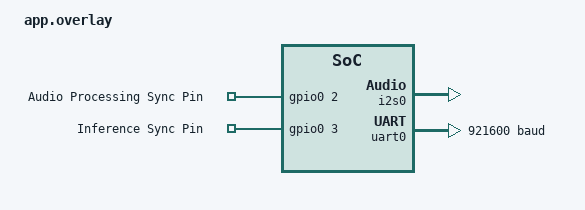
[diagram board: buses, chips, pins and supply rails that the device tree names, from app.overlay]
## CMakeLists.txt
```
# Copyright (c) 2026 Seeed Studio / Senior ML Engineer
# SPDX-License-Identifier: Apache-2.0

cmake_minimum_required(VERSION 3.20.0)

# Find Zephyr package
find_package(Zephyr REQUIRED HINTS $ENV{ZEPHYR_BASE})
project(streamable_kws_zephyr)

# Include esp-dl path (located in parent directory)
set(ESPDL_PATH ${CMAKE_CURRENT_SOURCE_DIR}/../esp-dl/esp-dl)
set(DL_FFT_PATH ${CMAKE_CURRENT_SOURCE_DIR}/../esp-dl/tools/dl_fft)

# ============================================================
# ESP-IDF HAL Paths (for PDM support)
# ============================================================
set(ESP_HAL_PATH ${CMAKE_CURRENT_SOURCE_DIR}/../zephyrproject/modules/hal/espressif)

target_include_directories(app PRIVATE
    src/compat
    ${ESPDL_PATH}/dl
    ${ESPDL_PATH}/dl/tool/include
    ${ESPDL_PATH}/dl/tensor/include
    ${ESPDL_PATH}/dl/base
    ${ESPDL_PATH}/dl/base/isa
    ${ESPDL_PATH}/dl/base/isa/tie728
    ${ESPDL_PATH}/dl/base/isa/xtensa
    ${ESPDL_PATH}/dl/math/include
    ${ESPDL_PATH}/dl/model/include
    ${ESPDL_PATH}/dl/module/include
    ${ESPDL_PATH}/fbs_loader/include
    ${ESPDL_PATH}/audio/common
    ${ESPDL_PATH}/audio/speech_features
    ${DL_FFT_PATH}
    ${DL_FFT_PATH}/base
    ${DL_FFT_PATH}/base/isa
    ${CMAKE_CURRENT_BINARY_DIR}
    src
    # ESP-IDF HAL includes - CORRECTED PATHS
    ${ESP_HAL_PATH}/components/esp_hal_i2s/include/hal
    ${ESP_HAL_PATH}/components/esp_common/include
    ${ESP_HAL_PATH}/components/driver/include
    ${ESP_HAL_PATH}/components/esp_hw_support/include
    ${ESP_HAL_PATH}/components/esp_hw_support/include/soc
    ${ESP_HAL_PATH}/components/soc/esp32s3/include
    ${ESP_HAL_PATH}/components/soc/include
    ${ESP_HAL_PATH}/components/esp_rom/include
    ${ESP_HAL_PATH}/components/esp_rom/include/esp32s3
    ${ESP_HAL_PATH}/components/esp_private/include
    ${ESP_HAL_PATH}/components/esp_hal_i2s/include
)

target_compile_definitions(app PRIVATE
    _USE_MATH_DEFINES
    _GNU_SOURCE
    M_PI=3.14159265358979323846
    # ESP-IDF definitions for HAL
    ESP_PLATFORM=1
    SOC_ESP32S3=1
    CONFIG_IDF_TARGET_ESP32S3=1
    CONFIG_SPIRAM=1
)

file(GLOB ESPDL_SRCS
    ${ESPDL_PATH}/dl/tool/src/*.cpp
    ${ESPDL_PATH}/dl/tool/isa/tie728/*.S
    ${ESPDL_PATH}/dl/tool/isa/xtensa/*.S
    ${ESPDL_PATH}/dl/tensor/src/*.cpp
    ${ESPDL_PATH}/dl/base/*.cpp
    ${ESPDL_PATH}/dl/base/isa/tie728/*.S
    ${ESPDL_PATH}/dl/base/isa/xtensa/*.S
    ${ESPDL_PATH}/dl/math/src/*.cpp
    ${ESPDL_PATH}/dl/model/src/*.cpp
    ${ESPDL_PATH}/dl/module/src/*.cpp
    ${ESPDL_PATH}/fbs_loader/src/*.cpp
    ${ESPDL_PATH}/audio/common/*.cpp
    ${ESPDL_PATH}/audio/speech_features/*.cpp
    ${DL_FFT_PATH}/*.c
    ${DL_FFT_PATH}/base/*.c
    ${DL_FFT_PATH}/base/isa/esp32s3/*.S
)

target_sources(app PRIVATE 
    src/main.cpp 
    src/audio_i2s.cpp
    src/audio_processing.cpp
    src/inference.cpp
    src/ble_server.c
    src/compat/posix_stubs.c
    src/compat/esp_heap_caps.cpp 
    ${ESPDL_SRCS}
)

# Link ESP-IDF HAL library if available
target_link_libraries(app PRIVATE 
    ${ESPDL_PATH}/fbs_loader/lib/esp32s3/libfbs_model.a
    "-Wl,--wrap=heap_caps_malloc"
    "-Wl,--wrap=heap_caps_free"
    "-Wl,--wrap=heap_caps_realloc"
    "-Wl,--wrap=heap_caps_calloc"
    "-Wl,--wrap=heap_caps_aligned_alloc"
    "-Wl,--wrap=heap_caps_aligned_free"
    "-Wl,--wrap=heap_caps_aligned_calloc"
    "-Wl,--wrap=heap_caps_get_free_size"
    "-Wl,--wrap=heap_caps_get_largest_free_block"
    "-Wl,--wrap=heap_caps_get_allocated_size"
    "-Wl,--wrap=heap_caps_get_total_size"
    "-Wl,--wrap=heap_caps_get_minimum_free_size"
    "-Wl,--wrap=heap_caps_get_info"
    "-Wl,--wrap=heap_caps_malloc_default"
    "-Wl,--wrap=heap_caps_realloc_default"
    "-Wl,--wrap=heap_caps_malloc_prefer"
    "-Wl,--wrap=heap_caps_realloc_prefer"
    "-Wl,--wrap=heap_caps_calloc_prefer"
    "-Wl,--wrap=heap_caps_register_failed_alloc_callback"
    "-Wl,--wrap=heap_caps_malloc_extmem_enable"
    "-Wl,--wrap=heap_caps_print_heap_info"
    "-Wl,--wrap=heap_caps_check_integrity"
    "-Wl,--wrap=heap_caps_check_integrity_all"
    "-Wl,--wrap=heap_caps_check_integrity_addr"
    "-Wl,--wrap=heap_caps_dump"
    "-Wl,--wrap=heap_caps_dump_all"
    "-Wl,--wrap=malloc"
    "-Wl,--wrap=free"
    "-Wl,--wrap=calloc"
    "-Wl,--wrap=realloc"
)

# Try to link ESP-IDF HAL libraries if they exist
if(EXISTS ${ESP_HAL_PATH}/components/esp_common/lib/esp32s3/libesp_common.a)
    target_link_libraries(app PRIVATE 
        ${ESP_HAL_PATH}/components/esp_common/lib/esp32s3/libesp_common.a
    )
endif()

if(EXISTS ${ESP_HAL_PATH}/components/driver/lib/esp32s3/libdriver.a)
    target_link_libraries(app PRIVATE 
        ${ESP_HAL_PATH}/components/driver/lib/esp32s3/libdriver.a
    )
endif()

generate_inc_file_for_target(app src/model.espdl ${CMAKE_CURRENT_BINARY_DIR}/model_espdl.inc)
```

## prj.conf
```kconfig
# C++ Support
CONFIG_CPP=y
CONFIG_STD_CPP20=y
CONFIG_REQUIRES_FULL_LIBCPP=y
CONFIG_NEWLIB_LIBC=y
# FPU Support
CONFIG_FPU=y
CONFIG_FPU_SHARING=y

# ESP32-S3 PSRAM - Use PSRAM for large allocations!
CONFIG_ESP_SPIRAM=y
CONFIG_SPIRAM_MODE_OCT=y
CONFIG_ESP_SPIRAM_HEAP_SIZE=4194304

# Memory - Optimized for DRAM (128 KB internal heap + 4 MB Octal PSRAM fallback)
CONFIG_HEAP_MEM_POOL_SIZE=131072
CONFIG_MAIN_STACK_SIZE=32768
CONFIG_SYSTEM_WORKQUEUE_STACK_SIZE=4096
CONFIG_IDLE_STACK_SIZE=2048
CONFIG_ISR_STACK_SIZE=4096

# Logging
CONFIG_LOG=y
CONFIG_LOG_DEFAULT_LEVEL=3
CONFIG_LOG_PRINTK=n
CONFIG_LOG_BUFFER_SIZE=8192
CONFIG_SERIAL=y
CONFIG_CONSOLE=y
CONFIG_UART_CONSOLE=y

# GPIO
CONFIG_GPIO=y

# I2S
CONFIG_I2S=y
CONFIG_I2S_ESP32=y
CONFIG_I2S_ESP32_RX_BLOCK_COUNT=32
CONFIG_DMA=y
CONFIG_DMA_ESP32=y

# Ring buffer
CONFIG_RING_BUFFER_LARGE=y

# Disable unnecessary features to save RAM
CONFIG_DEBUG_THREAD_INFO=n
CONFIG_THREAD_STACK_INFO=n
CONFIG_STACK_SENTINEL=n

# Speed Optimizations (Compile with -O2)
CONFIG_SPEED_OPTIMIZATIONS=y

# Bluetooth Low Energy (BLE) Server Configuration
CONFIG_BT=y
CONFIG_BT_PERIPHERAL=y
CONFIG_BT_DEVICE_NAME="XIAO_SENSE_BLE"

# BLE MTU and TX Buffer Configuration for Structured GATT Notifications (Expanded for Timestamps)
CONFIG_BT_L2CAP_TX_MTU=128
CONFIG_BT_BUF_ACL_TX_SIZE=132
CONFIG_BT_BUF_ACL_RX_SIZE=132
CONFIG_BT_BUF_ACL_TX_COUNT=10
CONFIG_BT_L2CAP_TX_BUF_COUNT=10
CONFIG_BT_CONN_TX_MAX=10
CONFIG_BT_GAP_AUTO_UPDATE_CONN_PARAMS=y
CONFIG_BT_PERIPHERAL_PREF_MIN_INT=24
CONFIG_BT_PERIPHERAL_PREF_MAX_INT=40
CONFIG_BT_PERIPHERAL_PREF_LATENCY=0
CONFIG_BT_PERIPHERAL_PREF_TIMEOUT=1000

# CPU Clock Frequency (160 MHz)
CONFIG_SYS_CLOCK_HW_CYCLES_PER_SEC=160000000
```

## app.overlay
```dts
/*
 * Device Tree Overlay for Seeed Studio XIAO ESP32-S3 Sense
 * I2S Microphone Pin Configuration (3-wire I2S RX Stream: BCK, SD, WS)
 */

#include <zephyr/dt-bindings/pinctrl/esp32s3-pinctrl.h>

/ {
	aliases {
		i2s-mic = &i2s0;
		sync-ap = &sync_ap_pin;
		sync-inf = &sync_inf_pin;
	};
	chosen {
		/delete-property/ zephyr,camera;
	};

	debug_pins {
		compatible = "gpio-keys";
		sync_ap_pin: sync_ap_pin {
			gpios = <&gpio0 2 GPIO_ACTIVE_HIGH>; /* GPIO2 (Pin D1) */
			label = "Audio Processing Sync Pin";
		};
		sync_inf_pin: sync_inf_pin {
			gpios = <&gpio0 3 GPIO_ACTIVE_HIGH>; /* GPIO3 (Pin D2) */
			label = "Inference Sync Pin";
		};
	};
};

&i2c1 {
	status = "disabled";
};

&lcd_cam {
	status = "disabled";
};

&lcd_cam_dvp {
	status = "disabled";
};


&pinctrl {
	i2s0_default: i2s0_default {
		group1 {
			pinmux =
				 <I2S0_I_WS_GPIO42>,
				 <I2S0_I_SD_GPIO41>;
		};
	};
};

&i2s0 {
	status = "okay";
	pinctrl-0 = <&i2s0_default>;
	pinctrl-names = "default";
};

&uart0 {
	status = "okay";
	current-speed = <921600>;
};

&cpu0 {
	clock-frequency = <160000000>;
};

&cpu1 {
	clock-frequency = <160000000>;
};
```

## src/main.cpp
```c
#include <zephyr/kernel.h>
#include <zephyr/logging/log.h>
#include <zephyr/drivers/gpio.h>
#include <cstring>
#include <cstdio>

#include "kws_config.hpp"
#include "audio_i2s.hpp"
#include "audio_processing.hpp"
#include "inference.hpp"
#include "ble_server.h"

LOG_MODULE_REGISTER(kws_app, LOG_LEVEL_INF);

/* Built-in LED: GPIO21, active-low (LED_ON = low, LED_OFF = high) */
#define LED0_NODE DT_ALIAS(led0)
static const struct gpio_dt_spec led = GPIO_DT_SPEC_GET(LED0_NODE, gpios);

int main(void)
{
    LOG_INF("==================================================");
    LOG_INF("  XIAO ESP32-S3 Sense: Streamable KWS (Zephyr + esp-dl)");
    LOG_INF("==================================================");

    /* --------------------------------------------------------
     * STARTUP BLINK: 3 fast blinks to confirm power-up and
     * firmware boot. Visible without a serial console.
     * -------------------------------------------------------- */
    if (device_is_ready(led.port)) {
        gpio_pin_configure_dt(&led, GPIO_OUTPUT_INACTIVE);
        for (int i = 0; i < 3; i++) {
            gpio_pin_set_dt(&led, 1);   /* LED ON  */
            k_sleep(K_MSEC(200));
            gpio_pin_set_dt(&led, 0);   /* LED OFF */
            k_sleep(K_MSEC(200));
        }
    }

    KWSInference kws_engine;
    if (!kws_engine.init()) {
        LOG_ERR("[FLAG: ERROR] KWS Inference engine initialization failed!");
        return -1;
    }

    if (!i2s_mic_init()) {
        LOG_ERR("[FLAG: ERROR] I2S PDM Microphone initialization failed!");
        return -1;
    }

    /* 
     * Initialize Bluetooth BLE Server.
     * This registers the custom BLE service and starts GAP advertising,
     * allowing the client board to discover and connect to us.
     */
    ble_server_init();

    LOG_INF("==================================================");
    LOG_INF("[FLAG: LIVE] Using real PDM microphone!");
    LOG_INF("Ready for real-time INT8 inference!");
    LOG_INF("==================================================");

    AudioProcessor audio_processor;

    int frame_counter = 0;
    int audio_buffer_index = 0;
    int16_t audio_pool[FRAME_SHIFT_SAMPLES] = {0};
    int16_t audio_window[FRAME_LEN_SAMPLES] = {0};

    while (1) {
        void *mem_block = nullptr;
        size_t block_size = 0;
        int ret = i2s_mic_read_block(&mem_block, &block_size);

        if (ret == 0 && mem_block != nullptr && block_size == I2S_BLOCK_SIZE) {
            uint8_t *byte_ptr = (uint8_t *)mem_block;
            
            for (int i = 0; i < SAMPLES_PER_BLOCK; i++) {
                int16_t raw_l = (int16_t)(byte_ptr[i * 8 + 2] | (byte_ptr[i * 8 + 3] << 8));
                int16_t raw_r = (int16_t)(byte_ptr[i * 8 + 6] | (byte_ptr[i * 8 + 7] << 8));
                
                int16_t clean_sample = audio_processor.process_sample_pair(raw_l, raw_r);

#if STREAM_RAW_PCM_MODE > 0
                int16_t stream_val = (STREAM_RAW_PCM_MODE == 1) ? raw_l : clean_sample;
                putchar(stream_val & 0xFF);
                putchar((stream_val >> 8) & 0xFF);
#else
                audio_pool[audio_buffer_index++] = clean_sample;

                if (audio_buffer_index >= FRAME_SHIFT_SAMPLES) {
                    audio_buffer_index = 0;

                    // Shift window
                    memmove(audio_window, audio_window + FRAME_SHIFT_SAMPLES, 
                            (FRAME_LEN_SAMPLES - FRAME_SHIFT_SAMPLES) * sizeof(int16_t));
                    
                    memcpy(audio_window + (FRAME_LEN_SAMPLES - FRAME_SHIFT_SAMPLES), 
                           audio_pool, FRAME_SHIFT_SAMPLES * sizeof(int16_t));

                    // --- Adaptive RMS VAD Noise-Floor Tracker ---
                    float sum_sq = 0.0f;
                    for (int s = 0; s < FRAME_SHIFT_SAMPLES; s++) {
                        sum_sq += (float)audio_pool[s] * (float)audio_pool[s];
                    }
                    float current_block_rms = sqrtf(sum_sq / (float)FRAME_SHIFT_SAMPLES);

                    static float ambient_noise_rms = 5.0f;
                    float adaptive_rms_threshold = ambient_noise_rms * 1.5f; // User multiplier 1.5x
                    if (adaptive_rms_threshold < 0.01f) {
                        adaptive_rms_threshold = 0.01f; // Safety floor
                    }

                    bool is_speech_active = (current_block_rms > adaptive_rms_threshold);

                    if (!is_speech_active) {
                        // Room is quiet: update ambient background noise floor safely
                        ambient_noise_rms = (0.995f * ambient_noise_rms) + (0.005f * current_block_rms);
                    }

                    bool log_details = (frame_counter % 100 == 0);
                    if (log_details) {
                        // LOG_INF("--- [FLAG: STAGE_1_START] Frame %d ---", frame_counter);
                    }

                    kws_engine.process_audio_window(audio_window, frame_counter, log_details);

                    frame_counter++;
                    if (frame_counter > 1000000) frame_counter = 0;
                }
#endif
            }
#if STREAM_RAW_PCM_MODE == 0
            audio_processor.check_and_report_diagnostics();
#endif
            i2s_mic_free_block(mem_block);
        } else {
            if (mem_block != nullptr) {
                i2s_mic_free_block(mem_block);
            }
            k_sleep(K_MSEC(1));
        }
    }
    return 0;
}
```

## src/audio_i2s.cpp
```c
/*
 * Copyright (c) 2026 Seeed Studio / Senior ML Engineer
 * SPDX-License-Identifier: Apache-2.0
 * 
 * audio_i2s.cpp - I2S driver wrapper for the PDM microphone on the Xiao ESP32-S3.
 * Configures the ESP32-S3 I2S peripheral in PDM RX mode, manages the DMA
 * memory slabs, and provides automatic recovery from audio stream underflows.
 */

#include "audio_i2s.hpp"
#include "kws_config.hpp"

#include <zephyr/kernel.h>
#include <zephyr/logging/log.h>
#include <zephyr/drivers/i2s.h>
#include <zephyr/drivers/gpio.h>

/* ESP32-S3 direct hardware register access definitions */
#include <soc/i2s_struct.h>
#include <soc/i2s_reg.h>

LOG_MODULE_DECLARE(kws_app, LOG_LEVEL_INF);

/* 
 * Define static memory slab pool for I2S DMA.
 * Allocates 32 blocks of I2S_BLOCK_SIZE bytes, aligned on 8-byte boundaries.
 */
K_MEM_SLAB_DEFINE_STATIC(rx_mem_slab, I2S_BLOCK_SIZE, 32, 8);

static const struct device *i2s_dev = nullptr;

/*
 * apply_pdm_regs: Directly configures the ESP32-S3 I2S hardware registers
 *                 to enable PDM-to-PCM demodulation and SINC decimation filter.
 */
static void apply_pdm_regs(void)
{
    I2S0.rx_conf.rx_pdm_en = 1;              // Enable PDM RX channel
    I2S0.rx_conf.rx_pdm2pcm_en = 1;          // Enable hardware PDM-to-PCM demodulator
    I2S0.rx_conf.rx_pdm_sinc_dsr_16_en = 1;  // Set oversampling rate to 16
    I2S0.rx_conf.rx_tdm_en = 0;              // Disable TDM mode
    I2S0.rx_conf.rx_mono = 0;                 // Disable Mono mode (read stereo)
    I2S0.rx_conf.rx_update = 1;              // Apply changes immediately
}

/*
 * full_i2s_reset: Performs a full hardware reset on the I2S peripheral,
 *                 clears the DMA queue, and restarts the audio capture.
 */
static void full_i2s_reset(void)
{
    LOG_WRN("Full I2S reset...");
    
    /* Stop DMA capture */
    i2s_trigger(i2s_dev, I2S_DIR_RX, I2S_TRIGGER_DROP);
    k_sleep(K_MSEC(10));
    
    /* Reset RX unit and FIFO */
    I2S0.rx_conf.rx_reset = 1;
    I2S0.rx_conf.rx_fifo_reset = 1;
    k_sleep(K_MSEC(10));
    I2S0.rx_conf.rx_reset = 0;
    I2S0.rx_conf.rx_fifo_reset = 0;
    
    /* Flush the DMA queue and free all allocated blocks */
    void *dummy;
    size_t dummy_size;
    while (i2s_read(i2s_dev, &dummy, &dummy_size) == 0 && dummy != NULL) {
        k_mem_slab_free(&rx_mem_slab, dummy);
    }
    
    apply_pdm_regs();
    
    /* Restart DMA capture */
    if (i2s_trigger(i2s_dev, I2S_DIR_RX, I2S_TRIGGER_START) != 0) {
        LOG_ERR("Failed to start I2S after reset!");
        return;
    }
    
    LOG_INF("I2S reset complete");
}

/*
 * i2s_mic_init: Gets the I2S device from the device tree, configures 
 *               the sampling rate, registers PDM settings, and starts capturing.
 */
bool i2s_mic_init(void)
{
    LOG_INF("[FLAG: STAGE_0_START] Initializing I2S PDM Microphone...");

    /* Get I2S device node from DTS */
    i2s_dev = DEVICE_DT_GET(DT_NODELABEL(i2s0));
    if (!device_is_ready(i2s_dev)) {
        LOG_ERR("[FLAG: ERROR] I2S device not ready!");
        return false;
    }
    LOG_INF("I2S device found: %s", i2s_dev->name);

    /* Setup I2S configuration parameters */
    struct i2s_config i2s_cfg = {
        .word_size = 16,
        .channels = 2,
        .format = I2S_FMT_DATA_FORMAT_I2S,
        .options = I2S_OPT_BIT_CLK_MASTER | I2S_OPT_FRAME_CLK_MASTER,
        .frame_clk_freq = SAMPLE_RATE * 8, // Set decimation clock frequency
        .mem_slab = &rx_mem_slab,
        .block_size = I2S_BLOCK_SIZE,
        .timeout = 1000,
    };

    if (i2s_configure(i2s_dev, I2S_DIR_RX, &i2s_cfg) != 0) {
        LOG_ERR("[FLAG: ERROR] Failed to configure I2S!");
        return false;
    }

    apply_pdm_regs();

    /* Trigger the I2S capture to start filling memory blocks via DMA */
    if (i2s_trigger(i2s_dev, I2S_DIR_RX, I2S_TRIGGER_START) != 0) {
        LOG_ERR("[FLAG: ERROR] Failed to start I2S!");
        return false;
    }

    k_sleep(K_MSEC(100));
    LOG_INF("[FLAG: SUCCESS] I2S started with PDM RX enabled!");
    return true;
}

/*
 * i2s_mic_read_block: Reads a processed PCM audio block from the DMA queue.
 *                     If reading fails (e.g. queue overflow or buffer underflow),
 *                     it triggers an automatic hardware reset to recover.
 */
int i2s_mic_read_block(void **mem_block, size_t *block_size)
{
    if (!i2s_dev) {
        return -1;
    }

    /* Force PDM register settings prior to reading to avoid hardware drift */
    apply_pdm_regs();

    int ret = i2s_read(i2s_dev, mem_block, block_size);
    
    /* Handle read failure or missing buffer pointers */
    if (ret != 0 || mem_block == NULL) {
        static int error_count = 0;
        error_count++;
        LOG_WRN("I2S read issue: ret=%d, mem_block=%p (count: %d)", ret, mem_block, error_count);
        
        /* Stop and reset the I2S capture pipeline */
        i2s_trigger(i2s_dev, I2S_DIR_RX, I2S_TRIGGER_DROP);
        k_sleep(K_MSEC(10));
        
        I2S0.rx_conf.rx_reset = 1;
        I2S0.rx_conf.rx_fifo_reset = 1;
        k_sleep(K_MSEC(10));
        I2S0.rx_conf.rx_reset = 0;
        I2S0.rx_conf.rx_fifo_reset = 0;
        
        apply_pdm_regs();
        
        if (i2s_trigger(i2s_dev, I2S_DIR_RX, I2S_TRIGGER_START) != 0) {
            LOG_ERR("Failed to start I2S after reset!");
            return -1;
        }
        
        /* Retry the read after resetting the pipeline */
        ret = i2s_read(i2s_dev, mem_block, block_size);
        if (ret != 0 || mem_block == NULL) {
            LOG_ERR("I2S still failing after reset! ret=%d", ret);
            return ret;
        }
        
        LOG_INF("I2S recovered successfully!");
    }
    
    return 0;
}

/*
 * i2s_mic_free_block: Frees the processed memory block back to the mem slab pool.
 */
void i2s_mic_free_block(void *mem_block)
{
    if (mem_block) {
        k_mem_slab_free(&rx_mem_slab, mem_block);
    }
}
```

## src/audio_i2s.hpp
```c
/*
 * Copyright (c) 2026 Seeed Studio / Senior ML Engineer
 * SPDX-License-Identifier: Apache-2.0
 */

#ifndef AUDIO_I2S_HPP
#define AUDIO_I2S_HPP

#include <cstddef>

/**
 * @brief Initialize the I2S PDM microphone device and memory slabs.
 * @return true if initialization succeeded, false otherwise.
 */
bool i2s_mic_init();

/**
 * @brief Read an audio block from the I2S microphone.
 * @param mem_block Output pointer to received memory block.
 * @param block_size Output pointer to size of received block.
 * @return 0 on success, negative error code on failure.
 */
int i2s_mic_read_block(void **mem_block, size_t *block_size);

/**
 * @brief Free a previously read I2S memory block.
 * @param mem_block Memory block to free.
 */
void i2s_mic_free_block(void *mem_block);

#endif // AUDIO_I2S_HPP
```

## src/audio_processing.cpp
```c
/*
 * Copyright (c) 2026 Seeed Studio / Senior ML Engineer
 * SPDX-License-Identifier: Apache-2.0
 * 
 * audio_processing.cpp - Real-time audio processing pipeline.
 * Performs gain scaling, soft-limiting, DC blocking high-pass filtering,
 * automatic microphone channel selection, and continuous diagnostic reporting.
 */

#include "audio_processing.hpp"
#include "kws_config.hpp"

#include <zephyr/logging/log.h>
#include <cmath>
#include <algorithm>

LOG_MODULE_DECLARE(kws_app, LOG_LEVEL_INF);

/*
 * Constructor: Initializes filter state variables and resets diagnostic counters.
 */
AudioProcessor::AudioProcessor()
    : use_right_channel(false), is_crossfading(false), crossfade_count(0), target_right_channel(false),
      hpf_x1_l(0.0f), hpf_y1_l(0.0f), hpf_x1_r(0.0f), hpf_y1_r(0.0f),
      lpf1_x1_l(0.0f), lpf1_x2_l(0.0f), lpf1_y1_l(0.0f), lpf1_y2_l(0.0f),
      lpf1_x1_r(0.0f), lpf1_x2_r(0.0f), lpf1_y1_r(0.0f), lpf1_y2_r(0.0f),
      lpf2_x1_l(0.0f), lpf2_x2_l(0.0f), lpf2_y1_l(0.0f), lpf2_y2_l(0.0f),
      lpf2_x1_r(0.0f), lpf2_x2_r(0.0f), lpf2_y1_r(0.0f), lpf2_y2_r(0.0f),
      prev_sample_l(0), prev_sample_r(0)
{
    reset_diagnostics();
}

/*
 * reset_diagnostics: Resets all running statistical registers used for logging.
 */
void AudioProcessor::reset_diagnostics()
{
    raw_sum_sq_l = 0; raw_sum_sq_r = 0;
    diag_sum_sq_l = 0; diag_sum_sq_r = 0;
    diag_sum_l = 0; diag_sum_r = 0;
    diag_min_l = 32767; diag_max_l = -32768;
    diag_min_r = 32767; diag_max_r = -32768;
    raw_min_l = 32767; raw_max_l = -32768;
    raw_min_r = 32767; raw_max_r = -32768;
    diag_zcr_l = 0; diag_zcr_r = 0;
    diag_clip_l = 0; diag_clip_r = 0;
    diag_sample_count = 0;
}

/*
 * process_sample_pair: Processes raw stereo PDM microphone samples (Left and Right).
 * 
 * Execution Steps:
 * 1. Accumulate raw input signal stats.
 * 2. Apply a Soft Limiter with a 0.35 gain scale to protect against digital clipping.
 * 3. Run a DC-blocking High-Pass Filter (cut-off ~80Hz) to filter out sub-bass rumble/DC offset.
 * 4. Accumulate clean signal stats (ZCR, peaks, sum of squares).
 * 5. Auto-Channel Lock: Locks on to the channel with higher speech energy after 1 second.
 * 6. Return the chosen channel's sample.
 */
int16_t AudioProcessor::process_sample_pair(int16_t raw_l, int16_t raw_r)
{
    raw_sum_sq_l += (int32_t)raw_l * (int32_t)raw_l;
    raw_sum_sq_r += (int32_t)raw_r * (int32_t)raw_r;
    
    if (raw_l < raw_min_l) raw_min_l = raw_l;
    if (raw_l > raw_max_l) raw_max_l = raw_l;
    if (raw_r < raw_min_r) raw_min_r = raw_r;
    if (raw_r > raw_max_r) raw_max_r = raw_r;

    // --- 1. Soft Limiter (Input stage) to prevent clipping / state overflow ---
    const float input_gain = 0.50f; // Boost sensitivity for 2.0m far-field speech
    const float in_limit = 16384.0f; // 6dB of headroom for close-up speech
    
    // Left Channel Input & Limit
    float in_l = (float)raw_l * input_gain;
    if (in_l > in_limit) {
        in_l = in_limit + (in_l - in_limit) / (1.0f + (in_l - in_limit) / (32767.0f - in_limit));
    } else if (in_l < -in_limit) {
        in_l = -in_limit + (in_l + in_limit) / (1.0f - (in_l + in_limit) / (32768.0f - in_limit));
    }

    // --- 2. DC Blocking HPF ---
    const float hpf_r = 0.968f; // ~80 Hz cutoff (blocks low-frequency hum, power line noise, and wind pops)
    float hpf_out_l = in_l - hpf_x1_l + hpf_r * hpf_y1_l;
    hpf_x1_l = in_l; hpf_y1_l = hpf_out_l;
 
    // --- 3. LPF (Bypassed: using hardware decimation) ---
    float out_l = hpf_out_l;
 
    if (out_l > 32767.0f) out_l = 32767.0f; else if (out_l < -32768.0f) out_l = -32768.0f;
    int16_t sample_l = (int16_t)out_l;
 
    // --- Right Channel Input & Limit ---
    float in_r = (float)raw_r * input_gain;
    if (in_r > in_limit) {
        in_r = in_limit + (in_r - in_limit) / (1.0f + (in_r - in_limit) / (32767.0f - in_limit));
    } else if (in_r < -in_limit) {
        in_r = -in_limit + (in_r + in_limit) / (1.0f - (in_r + in_limit) / (32768.0f - in_limit));
    }

    // DC Blocking HPF for Right Channel
    float hpf_out_r = in_r - hpf_x1_r + hpf_r * hpf_y1_r;
    hpf_x1_r = in_r; hpf_y1_r = hpf_out_r;
 
    // LPF (Bypassed: using hardware decimation) for Right Channel
    float out_r = hpf_out_r;
 
    if (out_r > 32767.0f) out_r = 32767.0f; else if (out_r < -32768.0f) out_r = -32768.0f;
    int16_t sample_r = (int16_t)out_r;
    
    // --- Lightweight O(1) Diagnostics Accumulation on Clean Signal ---
    diag_sum_l += sample_l;
    diag_sum_r += sample_r;
    diag_sum_sq_l += (int32_t)sample_l * (int32_t)sample_l;
    diag_sum_sq_r += (int32_t)sample_r * (int32_t)sample_r;
    
    if (sample_l < diag_min_l) diag_min_l = sample_l;
    if (sample_l > diag_max_l) diag_max_l = sample_l;
    if (sample_r < diag_min_r) diag_min_r = sample_r;
    if (sample_r > diag_max_r) diag_max_r = sample_r;
    
    // Track Zero-Crossing Rate (ZCR) for both channels to analyze hiss/high-frequency noise
    if ((sample_l >= 0 && prev_sample_l < 0) || (sample_l < 0 && prev_sample_l >= 0)) diag_zcr_l++;
    if ((sample_r >= 0 && prev_sample_r < 0) || (sample_r < 0 && prev_sample_r >= 0)) diag_zcr_r++;
    prev_sample_l = sample_l;
    prev_sample_r = sample_r;
    
    // Accumulate clipping occurrences
    if (sample_l <= -32000 || sample_l >= 32000) diag_clip_l++;
    if (sample_r <= -32000 || sample_r >= 32000) diag_clip_r++;
    
    diag_sample_count++;
    
    // Dynamically pick whichever channel contains active microphone signal (eliminates dead/floating channel static)
    int16_t active_sample = (abs(sample_l) >= abs(sample_r)) ? sample_l : sample_r;

    return active_sample;
}

/*
 * check_and_report_diagnostics: Prints a diagnostic report summarizing raw & post-filtered
 *                              signal properties (RMS, ZCR, clipping) every 10 seconds.
 */
void AudioProcessor::check_and_report_diagnostics()
{
    const int diag_report_interval = SAMPLE_RATE * 10;
    if (diag_sample_count >= diag_report_interval) {
        float raw_rms_l = sqrtf((float)raw_sum_sq_l / diag_sample_count);
        float raw_rms_r = sqrtf((float)raw_sum_sq_r / diag_sample_count);

        float mean_l = (float)diag_sum_l / diag_sample_count;
        float mean_r = (float)diag_sum_r / diag_sample_count;
        
        float var_l = ((float)diag_sum_sq_l / diag_sample_count) - (mean_l * mean_l);
        float var_r = ((float)diag_sum_sq_r / diag_sample_count) - (mean_r * mean_r);
        float rms_l = sqrtf(std::max(0.0f, var_l));
        float rms_r = sqrtf(std::max(0.0f, var_r));
        
        float dbfs_l = 20.0f * log10f(std::max(1.0f, rms_l) / 32768.0f);
        float dbfs_r = 20.0f * log10f(std::max(1.0f, rms_r) / 32768.0f);
        
        float zcr_pct_l = (100.0f * diag_zcr_l) / diag_sample_count;
        float zcr_pct_r = (100.0f * diag_zcr_r) / diag_sample_count;
        
        LOG_INF("================== AUDIO DIAGNOSIS REPORT (POST-FILTER) ==================");
        LOG_INF("Filter Active: DC Blocking HPF + 0.30x Input Gain + Limiter + 6kHz LPF");
        LOG_INF("Samples Analyzed: %d (~2.0 sec)", diag_sample_count);
        LOG_INF("Left  Ch (CH0) | Raw RMS: %6.1f, Raw Peak: [%6d, %6d] -> Clean RMS: %6.1f (%5.1f dBFS) | Peak: [%d, %d] | ZCR: %4.1f%% | Clips: %d",
                (double)raw_rms_l, raw_min_l, raw_max_l, (double)rms_l, (double)dbfs_l, diag_min_l, diag_max_l, (double)zcr_pct_l, diag_clip_l);
        LOG_INF("Right Ch (CH1) | Raw RMS: %6.1f, Raw Peak: [%6d, %6d] -> Clean RMS: %6.1f (%5.1f dBFS) | Peak: [%d, %d] | ZCR: %4.1f%% | Clips: %d",
                (double)raw_rms_r, raw_min_r, raw_max_r, (double)rms_r, (double)dbfs_r, diag_min_r, diag_max_r, (double)zcr_pct_r, diag_clip_r);
        
        if (rms_l < 10.0f && rms_r < 10.0f) {
            LOG_WRN("[DIAGNOSIS] Both channels have near-zero RMS. Mic may be disconnected, muted, or I2S clock mismatch!");
        } else if (rms_l > 500.0f && rms_r < 50.0f) {
            LOG_INF("[DIAGNOSIS] Active audio detected on LEFT channel (CH0).");
        } else if (rms_r > 500.0f && rms_l < 50.0f) {
            LOG_WRN("[DIAGNOSIS] Active audio is on RIGHT channel (CH1), but KWS is reading LEFT! Check mic channel strapping.");
        }
        
        if (zcr_pct_l > 35.0f || zcr_pct_r > 35.0f) {
            LOG_WRN("[DIAGNOSIS] High Zero-Crossing Rate (>35%%) detected. Indicates high-frequency white noise or clock hiss!");
        } else {
            LOG_INF("[DIAGNOSIS] ZCR is normal (<35%%). PDM high-frequency hiss successfully suppressed!");
        }
        if (diag_clip_l > 10 || diag_clip_r > 10) {
            LOG_WRN("[DIAGNOSIS] Signal clipping detected! Mic gain or PDM scaling is too high.");
        }
        LOG_INF("==========================================================================");
        
        reset_diagnostics();
    }
}
```

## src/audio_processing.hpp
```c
/*
 * Copyright (c) 2026 Seeed Studio / Senior ML Engineer
 * SPDX-License-Identifier: Apache-2.0
 */

#ifndef AUDIO_PROCESSING_HPP
#define AUDIO_PROCESSING_HPP

#include <cstdint>

class AudioProcessor {
public:
    AudioProcessor();

    /**
     * @brief Process a raw stereo sample pair from PDM mic: applies DC-blocking HPF,
     * 4th-order Butterworth LPF, updates diagnostics, dynamically selects active channel,
     * and returns the filtered sample of the active channel.
     * @param raw_l Raw left channel sample
     * @param raw_r Raw right channel sample
     * @return Filtered active channel sample
     */
    int16_t process_sample_pair(int16_t raw_l, int16_t raw_r);

    /**
     * @brief Check if diagnostic reporting threshold is reached and output diagnosis report if needed.
     */
    void check_and_report_diagnostics();

    /**
     * @brief Check whether the right channel (CH1) is currently active.
     */
    bool is_using_right_channel() const { return use_right_channel; }

private:
    void reset_diagnostics();

    bool use_right_channel;
    bool is_crossfading;
    int crossfade_count;
    bool target_right_channel;

    // Filter states
    float hpf_x1_l, hpf_y1_l;
    float hpf_x1_r, hpf_y1_r;
    float lpf1_x1_l, lpf1_x2_l, lpf1_y1_l, lpf1_y2_l;
    float lpf1_x1_r, lpf1_x2_r, lpf1_y1_r, lpf1_y2_r;
    float lpf2_x1_l, lpf2_x2_l, lpf2_y1_l, lpf2_y2_l;
    float lpf2_x1_r, lpf2_x2_r, lpf2_y1_r, lpf2_y2_r;

    // Diagnostics accumulators
    uint64_t diag_sum_sq_l, diag_sum_sq_r;
    uint64_t raw_sum_sq_l, raw_sum_sq_r;
    int64_t diag_sum_l, diag_sum_r;
    int16_t diag_min_l, diag_max_l;
    int16_t diag_min_r, diag_max_r;
    int16_t raw_min_l, raw_max_l;
    int16_t raw_min_r, raw_max_r;
    int diag_zcr_l, diag_zcr_r;
    int diag_clip_l, diag_clip_r;
    int16_t prev_sample_l, prev_sample_r;
    int diag_sample_count;
};

#endif // AUDIO_PROCESSING_HPP
```

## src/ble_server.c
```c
/**
 * @file ble_server.c
 * @brief Bluetooth Low Energy (BLE) Server implementation for Xiao ESP32-S3 Sense.
 *
 * Implements a GATT Server with a custom service for transmitting KWS results
 * (and raw audio logs) using Bluetooth Notifications (notify property).
 * Handles connection status tracking and transmission rate-limiting/chunking
 * to prevent stack overflow.
 *
 * @copyright Copyright (c) 2026 Seeed Studio
 * SPDX-License-Identifier: Apache-2.0
 */

#include "ble_server.h"
#include <zephyr/kernel.h>
#include <zephyr/bluetooth/bluetooth.h>
#include <zephyr/bluetooth/hci.h>
#include <zephyr/bluetooth/uuid.h>
#include <zephyr/bluetooth/gatt.h>
#include <stdio.h>

/* Custom UUID for the primary KWS BLE Service */
#define CUSTOM_SERVICE_UUID \
    BT_UUID_DECLARE_128(BT_UUID_128_ENCODE(0x12345678, 0x1234, 0x5678, 0x1234, 0x56789abcdef0))

/* Custom UUID for the notification characteristic */
#define CUSTOM_CHAR_UUID \
    BT_UUID_DECLARE_128(BT_UUID_128_ENCODE(0x12345678, 0x1234, 0x5678, 0x1234, 0x56789abcdef1))

/* State variables tracking active connection and subscriber subscription state */
static bool is_connected = false;
static bool notify_enabled = false;
static struct bt_conn *default_conn = NULL;

/**
 * @brief Callback invoked when the Client Characteristic Configuration Descriptor (CCCD) changes.
 *
 * Triggered when the connected peer enables or disables notifications.
 */
static void ccc_cfg_changed(const struct bt_gatt_attr *attr, uint16_t value) {
    notify_enabled = (value == BT_GATT_CCC_NOTIFY);
    printf("[BLE] Client notification (Notify) state changed: %s!\n", notify_enabled ? "ENABLED" : "DISABLED");
}

/* Primary Service and Characteristic definitions using Zephyr's macro API */
BT_GATT_SERVICE_DEFINE(my_custom_svc,
    BT_GATT_PRIMARY_SERVICE(CUSTOM_SERVICE_UUID),
    BT_GATT_CHARACTERISTIC(CUSTOM_CHAR_UUID, BT_GATT_CHRC_NOTIFY, BT_GATT_PERM_NONE, NULL, NULL, NULL),
    BT_GATT_CCC(ccc_cfg_changed, BT_GATT_PERM_READ | BT_GATT_PERM_WRITE)
);

#include "kws_config.hpp"

static char ble_dev_name[] = CONFIG_CUSTOM_DEVICE_NAME;

/* 
 * Live Probability Payload inside BLE Manufacturer Advertising Data:
 * Index 0-1: Company Identifier (0xFFFF - Special Test ID)
 * Index 2:   Device ID (1 for XIAO_SENSE_BLE_1, 2 for XIAO_SENSE_BLE_2)
 * Index 3:   Sequence Counter
 * Index 4..8: Class Probabilities in % (0-100) for [go, stop, left, right, nothing]
 */
static uint8_t mfg_data[9] = { 0xFF, 0xFF, DEVICE_ID, 0, 0, 0, 0, 0, 100 };

/* GAP Advertising packets config */
static struct bt_data ad[] = {
    BT_DATA_BYTES(BT_DATA_FLAGS, (BT_LE_AD_GENERAL | BT_LE_AD_NO_BREDR)),
    BT_DATA(BT_DATA_MANUFACTURER_DATA, mfg_data, sizeof(mfg_data)),
};

/* Scan Response packet carrying the custom device name */
static struct bt_data sd[] = {
    BT_DATA(BT_DATA_NAME_COMPLETE, ble_dev_name, sizeof(ble_dev_name) - 1),
};

/* 
 * Fast BLE Advertising Parameters:
 * 40 - 80 units (25ms to 50ms interval) for ultra-fast, low-latency late fusion updates.
 */
#define MY_ADV_PARAM BT_LE_ADV_PARAM(BT_LE_ADV_OPT_CONN, \
                                     40, \
                                     80, \
                                     NULL)

/**
 * @brief Callback invoked when a connection is established.
 */
static void connected(struct bt_conn *conn, uint8_t err) {
    if (!err) {
        if (default_conn != NULL) {
            bt_conn_unref(default_conn);
        }
        default_conn = bt_conn_ref(conn);
        is_connected = true;
        printf("\n[BLE] >>> CENTRAL DEVICE CONNECTED (%s)! <<<\n", ble_dev_name);
    }
}

/**
 * @brief Callback invoked when a connection is terminated.
 */
static void disconnected(struct bt_conn *conn, uint8_t reason) {
    if (default_conn != NULL) {
        bt_conn_unref(default_conn);
        default_conn = NULL;
    }
    is_connected = false;
    notify_enabled = false;
    printf("\n[BLE] --- CONNECTION LOST (Reason: 0x%02X) ---\n", reason);
    
    /* Restart advertising */
    int err = bt_le_adv_start(MY_ADV_PARAM, ad, ARRAY_SIZE(ad), sd, ARRAY_SIZE(sd));
    if (err == 0) {
        printf("[BLE] Advertising restarted for %s.\n", ble_dev_name);
    } else {
        printf("[BLE ERROR] Failed to restart advertising (err: %d)\n", err);
    }
}

/* Register connection callbacks */
BT_CONN_CB_DEFINE(conn_callbacks) = {
    .connected = connected,
    .disconnected = disconnected,
};

void ble_server_init(void) {
    /* Initialize the Bluetooth Subsystem */
    int err = bt_enable(NULL);
    if (err) {
        printf("[BLE ERROR] Initialization failed (err: %d)\n", err);
        return;
    }

    bt_set_name(CONFIG_CUSTOM_DEVICE_NAME);
    
    /* Start advertising our presence to scanning clients */
    err = bt_le_adv_start(MY_ADV_PARAM, ad, ARRAY_SIZE(ad), sd, ARRAY_SIZE(sd));
    if (err == 0) {
        printf("[BLE] Advertising started for [%s] (ID: %d).\n", CONFIG_CUSTOM_DEVICE_NAME, DEVICE_ID);
    } else {
        printf("[BLE ERROR] Failed to start advertising (err: %d)\n", err);
    }
}

bool ble_is_connected_and_ready(void) {
    return (is_connected && notify_enabled);
}

void ble_send_audio_data(int16_t *data, int total_samples) {
    int samples_sent = 0;
    
    /* 
     * MEMORY AND FLOW CONTROL TUNING:
     * High data rates can saturate the HCI TX ring buffers, causing memory exhaustion
     * (-ENOMEM/-ENOBUFS). We chunk data into 10 samples (20 Bytes), which fits
     * cleanly within the standard BLE MTU (23 bytes) without fragmentation.
     */
    int chunk_size = 10; 
    int enomem_count = 0;

    printf("\n[BLE] Transmitting %d PCM audio samples over BLE...\n", total_samples);

    while (samples_sent < total_samples && ble_is_connected_and_ready()) {
        int to_send = total_samples - samples_sent;
        if (to_send > chunk_size) {
            to_send = chunk_size;
        }

        /* Send notification using characteristic index 2 */
        int ret = bt_gatt_notify(NULL, &my_custom_svc.attrs[2], &data[samples_sent], to_send * sizeof(int16_t));

        if (ret == 0) {
            samples_sent += to_send;
            enomem_count = 0; /* Reset error counter on success */
            k_sleep(K_MSEC(5)); /* Brief sleep to let the RF controller process the packet */
            
        } else if (ret == -ENOMEM || ret == -ENOBUFS || ret == -EAGAIN) {
            /* Congestion detected: back off and wait for TX buffers to clear */
            enomem_count++;
            if (enomem_count % 50 == 0) {
                printf("[BLE WARNING] Buffer congestion! Retrying at sample %d...\n", samples_sent);
            }
            k_sleep(K_MSEC(20)); /* Sleep longer to allow channel clearance */
            
        } else {
            /* Fatal transmission error */
            printf("[BLE FATAL] Notification rejected! (err: %d)\n", ret);
            k_sleep(K_MSEC(100));
        }
    }
    printf("\n[BLE] Transmission complete! All audio packets sent.\n");
}

void ble_send_binary(const void *data, uint16_t len) {
    if (is_connected && default_conn != NULL && data != NULL && len > 0) {
        /* Send binary packet notification using valid connection handle default_conn and value attr attrs[2] */
        bt_gatt_notify(default_conn, &my_custom_svc.attrs[2], data, len);
    }
}

void ble_send_string(const char *str) {
    if (is_connected && default_conn != NULL) {
        int len = strlen(str);
        /* Send string notification using valid connection handle default_conn and value attr attrs[2] */
        bt_gatt_notify(default_conn, &my_custom_svc.attrs[2], str, len);
    }
}

void ble_update_probabilities(const float *probs, int num_classes) {
    if (!probs) return;
    mfg_data[2] = DEVICE_ID;
    mfg_data[3]++; // Increment sequence counter
    for (int i = 0; i < 5 && i < num_classes; i++) {
        int pct = (int)(probs[i] * 100.0f + 0.5f);
        if (pct < 0) pct = 0;
        if (pct > 100) pct = 100;
        mfg_data[4 + i] = (uint8_t)pct;
    }
    bt_le_adv_update_data(ad, ARRAY_SIZE(ad), sd, ARRAY_SIZE(sd));
}
```

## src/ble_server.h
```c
/**
 * @file ble_server.h
 * @brief Bluetooth Low Energy (BLE) Server interface for Xiao ESP32-S3 Sense.
 *
 * This header declares the functions required to initialize, manage, and transmit
 * data over a custom BLE service. It supports both raw audio chunk streaming
 * and text-based KWS detection result transmission.
 *
 * @copyright Copyright (c) 2026 Seeed Studio
 * SPDX-License-Identifier: Apache-2.0
 */

#ifndef BLE_SERVER_H
#define BLE_SERVER_H

#include <stdbool.h>
#include <stdint.h>

#ifdef __cplusplus
extern "C" {
#endif

/**
 * @brief Initializes the Bluetooth controller and starts GAP advertising.
 *
 * This function enables the Bluetooth stack and registers the GAP advertising
 * packet containing the device name ("XIAO_SENSE_BLE").
 */
void ble_server_init(void);

/**
 * @brief Checks if a client is connected and has enabled notifications.
 *
 * @return true if a peer is connected and the Client Characteristic Configuration
 *         Descriptor (CCCD) has notifications enabled, false otherwise.
 */
bool ble_is_connected_and_ready(void);

/**
 * @brief Transmits raw PCM audio data chunks to the connected client.
 *
 * Splits the raw audio samples into BLE-friendly small chunks (e.g. 20 bytes/10 samples)
 * to avoid queue/heap congestion, and notifies the subscriber.
 *
 * @param data Pointer to the array of 16-bit PCM audio samples.
 * @param total_samples Total number of samples to transmit.
 */
void ble_send_audio_data(int16_t *data, int total_samples);

/**
 * @brief 10-Byte Bit-Packed Binary GATT Notification Packet
 */
struct __attribute__((packed)) BleKwsPacket {
    uint8_t  dev_id;      /**< Device ID (1, 2, 3) */
    uint8_t  top_class;   /**< Class Index (0=go, 1=stop, 2=left, 3=right, 4=nothing) */
    uint8_t  conf;        /**< Top Confidence (0 to 100%) */
    uint8_t  rms;         /**< Audio RMS intensity (0 to 255) */
    uint16_t noise_x1k;   /**< Linear Noise Floor * 1000 */
    uint32_t ts_ms;       /**< Hardware timestamp in ms (k_uptime_get_32()) */
};

/**
 * @brief Transmits raw binary packet to the connected client.
 *
 * @param data Pointer to binary data buffer.
 * @param len Length in bytes.
 */
void ble_send_binary(const void *data, uint16_t len);

/**
 * @brief Transmits a formatted detection string to the connected client.
 *
 * Sends a null-terminated string (e.g. keyword + confidence) over the custom
 * BLE GATT notification characteristic.
 *
 * @param str Null-terminated string to be sent.
 */
void ble_send_string(const char *str);

/**
 * @brief Updates the live probability scores in the BLE Manufacturer Advertising payload.
 *
 * @param probs Array of class probabilities (5 classes).
 * @param num_classes Number of classes in probs.
 */
void ble_update_probabilities(const float *probs, int num_classes);

#ifdef __cplusplus
}
#endif

#endif // BLE_SERVER_H
```

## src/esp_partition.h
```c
/*
 * Copyright (c) 2026 Seeed Studio / Senior ML Engineer
 * SPDX-License-Identifier: Apache-2.0
 *
 * @file esp_partition.h
 * @brief Zephyr RTOS compatibility wrapper for ESP-IDF's esp_partition.h.
 *
 * ESP-DL's Model loader (fbs_loader) relies on the ESP-IDF partition API
 * to locate, map, and read model binaries from flash storage partitions.
 * 
 * In this Zephyr implementation, we compile and store the model directly in 
 * the Flash Read-Only Data (RODATA) segment. Therefore, we do not have a physical 
 * ESP-IDF partition table.
 * 
 * This compatibility header stub out the partition mapping APIs cleanly:
 * - esp_partition_find_first: Always returns NULL (no partition found).
 * - esp_partition_mmap: Bypasses the partition lookup and maps the memory address 
 *   offset directly to the output pointer.
 * - esp_partition_munmap: Idle stub.
 */

#pragma once

#include <zephyr/kernel.h>
#include <stddef.h>
#include <stdint.h>
#include "spi_flash_mmap.h"

#ifdef __cplusplus
extern "C" {
#endif

/**
 * @brief Handle representing a mapped memory region.
 */
typedef uint32_t esp_partition_mmap_handle_t;

/**
 * @brief ESP-IDF style partition descriptor structure.
 */
typedef struct {
    uint32_t size;      /**< Partition size in bytes */
    const char *label;  /**< Partition text label */
} esp_partition_t;

/**
 * @brief ESP-IDF style partition type enumeration.
 */
typedef enum {
    ESP_PARTITION_TYPE_DATA = 0
} esp_partition_type_t;

/**
 * @brief ESP-IDF style partition subtype enumeration.
 */
typedef enum {
    ESP_PARTITION_SUBTYPE_ANY = 0
} esp_partition_subtype_t;

/**
 * @brief Re-map the spi_flash memory structure.
 */
typedef spi_flash_mmap_memory_t esp_partition_mmap_memory_t;
#define ESP_PARTITION_MMAP_DATA SPI_FLASH_MMAP_DATA

/**
 * @brief Stubs partition lookup.
 * @return Always returns NULL since partitions are not managed via tables in Zephyr.
 */
static inline const esp_partition_t *esp_partition_find_first(esp_partition_type_t type,
                                                              esp_partition_subtype_t subtype,
                                                              const char *label)
{
    return NULL;
}

/**
 * @brief Maps a flash offset to a virtual memory address.
 * 
 * In our RODATA-based model setup, the offset parameter is the direct memory pointer.
 * Therefore, we assign the offset directly to the output pointer.
 *
 * @param partition Unused.
 * @param offset Direct flash pointer offset.
 * @param size Unused.
 * @param memory Unused.
 * @param out_ptr Pointer to receive the mapped memory address.
 * @param out_handle Pointer to receive the mapping handle.
 * @return Always returns 0 (Success).
 */
static inline int esp_partition_mmap(const esp_partition_t *partition, uint32_t offset,
                                     uint32_t size, esp_partition_mmap_memory_t memory,
                                     const void **out_ptr, esp_partition_mmap_handle_t *out_handle)
{
    *out_ptr = (const void *)offset;
    *out_handle = 1;
    return 0;
}

/**
 * @brief Unmaps a previously mapped flash memory region.
 * @param handle Unused.
 */
static inline void esp_partition_munmap(esp_partition_mmap_handle_t handle)
{
    (void)handle;
}

#ifdef __cplusplus
}
#endif
```

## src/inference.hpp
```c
/*
 * Copyright (c) 2026 Seeed Studio / Senior ML Engineer
 * SPDX-License-Identifier: Apache-2.0
 */

#ifndef INFERENCE_HPP
#define INFERENCE_HPP

#include "dl_model_base.hpp"
#include "dl_tensor_base.hpp"
#include "dl_fbank.hpp"
#include <cstdint>

class KWSInference {
public:
    KWSInference();
    ~KWSInference();

    /**
     * @brief Initialize neural network model, Mel filterbank, and PSRAM sliding window buffer.
     * @return true on success, false on failure.
     */
    bool init();

    /**
     * @brief Process an audio frame (256 samples), extract Fbank features, update sliding window,
     * and run KWS inference every INFERENCE_STRIDE frames.
     * @param audio_window Array of 256 audio samples (int16_t).
     * @param frame_counter Current frame counter.
     * @param log_details Whether detailed frame logs should be printed.
     */
    void process_audio_window(const int16_t *audio_window, int frame_counter, bool log_details);

private:
    void compute_softmax(const float *logits, float *probs, int len);

    dl::Model *model;
    dl::audio::Fbank *fbank;
    dl::TensorBase *input_tensor;
    dl::TensorBase *output_tensor;
    float *sliding_window_buf;
    float *normalized_buf;
    int cooldown_counter;
    int last_detected_class;
    int consecutive_count;
    int dropout_count;

    // Timing diagnostic variables
    uint32_t last_ap_start;
    uint32_t last_ap_end;
    double last_ap_time_ms;

    uint32_t last_inf_start;
    uint32_t last_inf_end;
    double last_inf_time_ms;
};

#endif // INFERENCE_HPP
```

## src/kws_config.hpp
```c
/*
 * Copyright (c) 2026 Seeed Studio / Senior ML Engineer
 * SPDX-License-Identifier: Apache-2.0
 */

#ifndef KWS_CONFIG_HPP
#define KWS_CONFIG_HPP

#ifdef __cplusplus
#include <cstddef>
#include <cstdint>
#else
#include <stddef.h>
#include <stdint.h>
#endif

#define SAMPLE_RATE 16000
#define FRAME_LEN_SAMPLES 256
#define FRAME_SHIFT_SAMPLES 160
#define NUM_MEL_BINS 40
#define TIME_FRAMES 100

#define I2S_BLOCK_SIZE 1024
#define SAMPLES_PER_BLOCK 128

// ============================================================================
// TOPOLOGY SELECTION:
// 0: Homogeneous 36-Class Generalist (Legacy)
// 1: Universal Overlap 25-Class MoE (Optimal Energy & 91.2% Spatial Accuracy)
// ============================================================================
#define USE_GRAPH_COUPLED_MOE 1

#if USE_GRAPH_COUPLED_MOE
#define NUM_CLASSES 25
#define NOTHING_CLASS_INDEX 24              // Index of 'nothing' (silence) class
#else
#define NUM_CLASSES 36
#define NOTHING_CLASS_INDEX 35              // Index of 'nothing' (silence) class
#endif

#define CONFIDENCE_THRESHOLD 0.50f          // Keyword confidence threshold
#define NOTHING_TRIGGER_THRESHOLD 0.30f     // If nothing > 30%, definitely silence
#define CONFIDENCE_MARGIN 0.15f             // Minimum margin over second best class (15%)
#define COOLDOWN_FRAMES 15                  // 150ms cooldown after keyword detection
#define INFERENCE_STRIDE 6
#define VOICE_ACTIVITY_RMS_THRESHOLD 5.0f // Energy squelch: skip model run if RMS < threshold

// ============================================================================
// MULTI-DEVICE CONFIGURATION FOR LATE FUSION
// Set DEVICE_ID to 1 for Device 1 (XIAO_SENSE_BLE_1)
// Set DEVICE_ID to 2 for Device 2 (XIAO_SENSE_BLE_2)
// Set DEVICE_ID to 3 for Device 3 (XIAO_SENSE_BLE_3)
// ============================================================================
#ifndef DEVICE_ID
#define DEVICE_ID 3
#endif

#if DEVICE_ID == 3
#define CONFIG_CUSTOM_DEVICE_NAME "XIAO_SENSE_BLE_3"
#elif DEVICE_ID == 2
#define CONFIG_CUSTOM_DEVICE_NAME "XIAO_SENSE_BLE_2"
#else
#define CONFIG_CUSTOM_DEVICE_NAME "XIAO_SENSE_BLE_1"
#endif

// ============================================================================
// AUDIO STREAMING TEST MODE (For Audacity Analysis via record_to_wav.py)
// ============================================================================
// 0: Normal KWS Inference Mode (ASCII serial logs enabled)
// 1: Stream PRE-FILTER Raw PCM over Serial (Before DC-Block HPF & Butterworth LPF)
// 2: Stream POST-FILTER Clean PCM over Serial (After DC-Block HPF & Butterworth LPF)
#define STREAM_RAW_PCM_MODE 0

#endif // KWS_CONFIG_HPP
```
